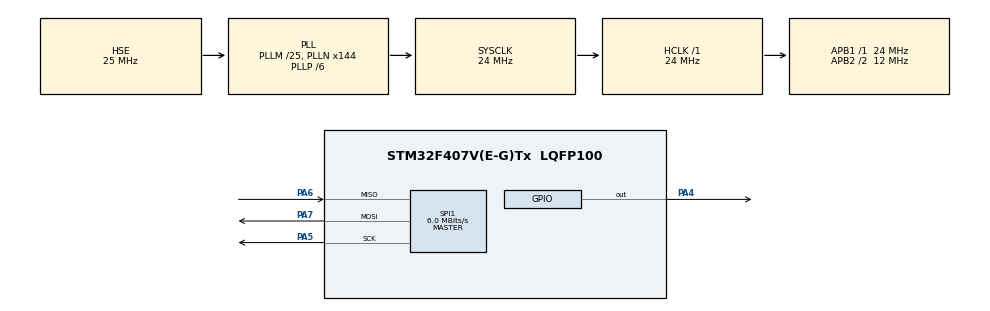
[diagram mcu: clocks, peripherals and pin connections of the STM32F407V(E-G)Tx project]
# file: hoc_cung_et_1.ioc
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Mcu.Family=STM32F4
Mcu.Name=STM32F407V(E-G)Tx
Mcu.Package=LQFP100
NVIC.PriorityGroup=NVIC_PRIORITYGROUP_4
PA13.Mode=Serial_Wire
PA13.Signal=SYS_JTMS-SWDIO
PA14.Mode=Serial_Wire
PA14.Signal=SYS_JTCK-SWCLK
PA4.Signal=GPIO_Output
PA5.Mode=Full_Duplex_Master
PA5.Signal=SPI1_SCK
PA6.Mode=Full_Duplex_Master
PA6.Signal=SPI1_MISO
PA7.Mode=Full_Duplex_Master
PA7.Signal=SPI1_MOSI
PH0-OSC_IN.Mode=HSE-External-Oscillator
PH0-OSC_IN.Signal=RCC_OSC_IN
PH1-OSC_OUT.Mode=HSE-External-Oscillator
PH1-OSC_OUT.Signal=RCC_OSC_OUT
ProjectManager.HeapSize=0x200
ProjectManager.StackSize=0x400
ProjectManager.TargetToolchain=MDK-ARM V5.32
RCC.48MHZClocksFreq_Value=36000000
RCC.AHBFreq_Value=24000000
RCC.APB1Freq_Value=24000000
RCC.APB1TimFreq_Value=24000000
RCC.APB2CLKDivider=RCC_HCLK_DIV2
RCC.APB2Freq_Value=12000000
RCC.APB2TimFreq_Value=24000000
RCC.CortexFreq_Value=24000000
RCC.HCLKFreq_Value=24000000
RCC.HSE_VALUE=25000000
RCC.HSI_VALUE=16000000
RCC.LSE_VALUE=32768
RCC.PLLM=25
RCC.PLLN=144
RCC.PLLP=RCC_PLLP_DIV6
RCC.PLLSourceVirtual=RCC_PLLSOURCE_HSE
RCC.SYSCLKFreq_VALUE=24000000
RCC.SYSCLKSource=RCC_SYSCLKSOURCE_PLLCLK
RCC.VCOOutputFreq_Value=144000000
SPI1.CalculateBaudRate=6.0 MBits/s
SPI1.Direction=SPI_DIRECTION_2LINES
SPI1.Mode=SPI_MODE_MASTER
SPI1.VirtualType=VM_MASTER
board=custom

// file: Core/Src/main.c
/* USER CODE BEGIN Header */
/**
  ******************************************************************************
  * @file           : main.c
  * @brief          : Main program body
  ******************************************************************************
  * @attention
  *
  * Copyright (c) 2025 STMicroelectronics.
  * All rights reserved.
  *
  * This software is licensed under terms that can be found in the LICENSE file
  * in the root directory of this software component.
  * If no LICENSE file comes with this software, it is provided AS-IS.
  *
  ******************************************************************************
  */
/* USER CODE END Header */
#include "main.h"

SPI_HandleTypeDef hspi1;

void SystemClock_Config(void);
static void MX_GPIO_Init(void);
static void MX_SPI1_Init(void);

/* USER CODE BEGIN 0 */
#define u8 uint8_t

void send_data_spi(u8 data){
	HAL_GPIO_WritePin(GPIOA, GPIO_PIN_4, GPIO_PIN_RESET);
	// Truyen du lieu
	HAL_SPI_Transmit(&hspi1, &data, 1, 1000);
	HAL_GPIO_WritePin(GPIOA, GPIO_PIN_4, GPIO_PIN_SET);
}

/* USER CODE END 0 */

int main(void)
{

  /* MCU Configuration--------------------------------------------------------*/

  /* Reset of all peripherals, Initializes the Flash interface and the Systick. */
  HAL_Init();

  /* Configure the system clock */
  SystemClock_Config();

  /* Initialize all configured peripherals */
  MX_GPIO_Init();
  MX_SPI1_Init();

  /* Infinite loop */
  while (1)
  {

    /* USER CODE BEGIN 3 */
		send_data_spi(0x09);
		HAL_Delay(500);
  }
  /* USER CODE END 3 */
}

void SystemClock_Config(void)
{
  RCC_OscInitTypeDef RCC_OscInitStruct = {0};
  RCC_ClkInitTypeDef RCC_ClkInitStruct = {0};

  /** Configure the main internal regulator output voltage
  */
  __HAL_RCC_PWR_CLK_ENABLE();
  __HAL_PWR_VOLTAGESCALING_CONFIG(PWR_REGULATOR_VOLTAGE_SCALE1);

  /** Initializes the RCC Oscillators according to the specified parameters
  * in the RCC_OscInitTypeDef structure.
  */
  RCC_OscInitStruct.OscillatorType = RCC_OSCILLATORTYPE_HSE;
  RCC_OscInitStruct.HSEState = RCC_HSE_ON;
  RCC_OscInitStruct.PLL.PLLState = RCC_PLL_ON;
  RCC_OscInitStruct.PLL.PLLSource = RCC_PLLSOURCE_HSE;
  RCC_OscInitStruct.PLL.PLLM = 25;
  RCC_OscInitStruct.PLL.PLLN = 144;
  RCC_OscInitStruct.PLL.PLLP = RCC_PLLP_DIV6;
  RCC_OscInitStruct.PLL.PLLQ = 4;
  if (HAL_RCC_OscConfig(&RCC_OscInitStruct) != HAL_OK)
  {
    Error_Handler();
  }

  /** Initializes the CPU, AHB and APB buses clocks
  */
  RCC_ClkInitStruct.ClockType = RCC_CLOCKTYPE_HCLK|RCC_CLOCKTYPE_SYSCLK
                              |RCC_CLOCKTYPE_PCLK1|RCC_CLOCKTYPE_PCLK2;
  RCC_ClkInitStruct.SYSCLKSource = RCC_SYSCLKSOURCE_PLLCLK;
  RCC_ClkInitStruct.AHBCLKDivider = RCC_SYSCLK_DIV1;
  RCC_ClkInitStruct.APB1CLKDivider = RCC_HCLK_DIV1;
  RCC_ClkInitStruct.APB2CLKDivider = RCC_HCLK_DIV2;

  if (HAL_RCC_ClockConfig(&RCC_ClkInitStruct, FLASH_LATENCY_0) != HAL_OK)
  {
    Error_Handler();
  }
}

static void MX_SPI1_Init(void)
{

  /* SPI1 parameter configuration*/
  hspi1.Instance = SPI1;
  hspi1.Init.Mode = SPI_MODE_MASTER;
  hspi1.Init.Direction = SPI_DIRECTION_2LINES;
  hspi1.Init.DataSize = SPI_DATASIZE_8BIT;
  hspi1.Init.CLKPolarity = SPI_POLARITY_LOW;
  hspi1.Init.CLKPhase = SPI_PHASE_1EDGE;
  hspi1.Init.NSS = SPI_NSS_SOFT;
  hspi1.Init.BaudRatePrescaler = SPI_BAUDRATEPRESCALER_2;
  hspi1.Init.FirstBit = SPI_FIRSTBIT_MSB;
  hspi1.Init.TIMode = SPI_TIMODE_DISABLE;
  hspi1.Init.CRCCalculation = SPI_CRCCALCULATION_DISABLE;
  hspi1.Init.CRCPolynomial = 10;
  if (HAL_SPI_Init(&hspi1) != HAL_OK)
  {
    Error_Handler();
  }

}

static void MX_GPIO_Init(void)
{
  GPIO_InitTypeDef GPIO_InitStruct = {0};

  /* GPIO Ports Clock Enable */
  __HAL_RCC_GPIOH_CLK_ENABLE();
  __HAL_RCC_GPIOA_CLK_ENABLE();

  /*Configure GPIO pin Output Level */
  HAL_GPIO_WritePin(GPIOA, GPIO_PIN_4, GPIO_PIN_RESET);

  /*Configure GPIO pin : PA4 */
  GPIO_InitStruct.Pin = GPIO_PIN_4;
  GPIO_InitStruct.Mode = GPIO_MODE_OUTPUT_PP;
  GPIO_InitStruct.Pull = GPIO_NOPULL;
  GPIO_InitStruct.Speed = GPIO_SPEED_FREQ_LOW;
  HAL_GPIO_Init(GPIOA, &GPIO_InitStruct);

}

void Error_Handler(void)
{
  __disable_irq();
  while (1)
  {
  }
}
